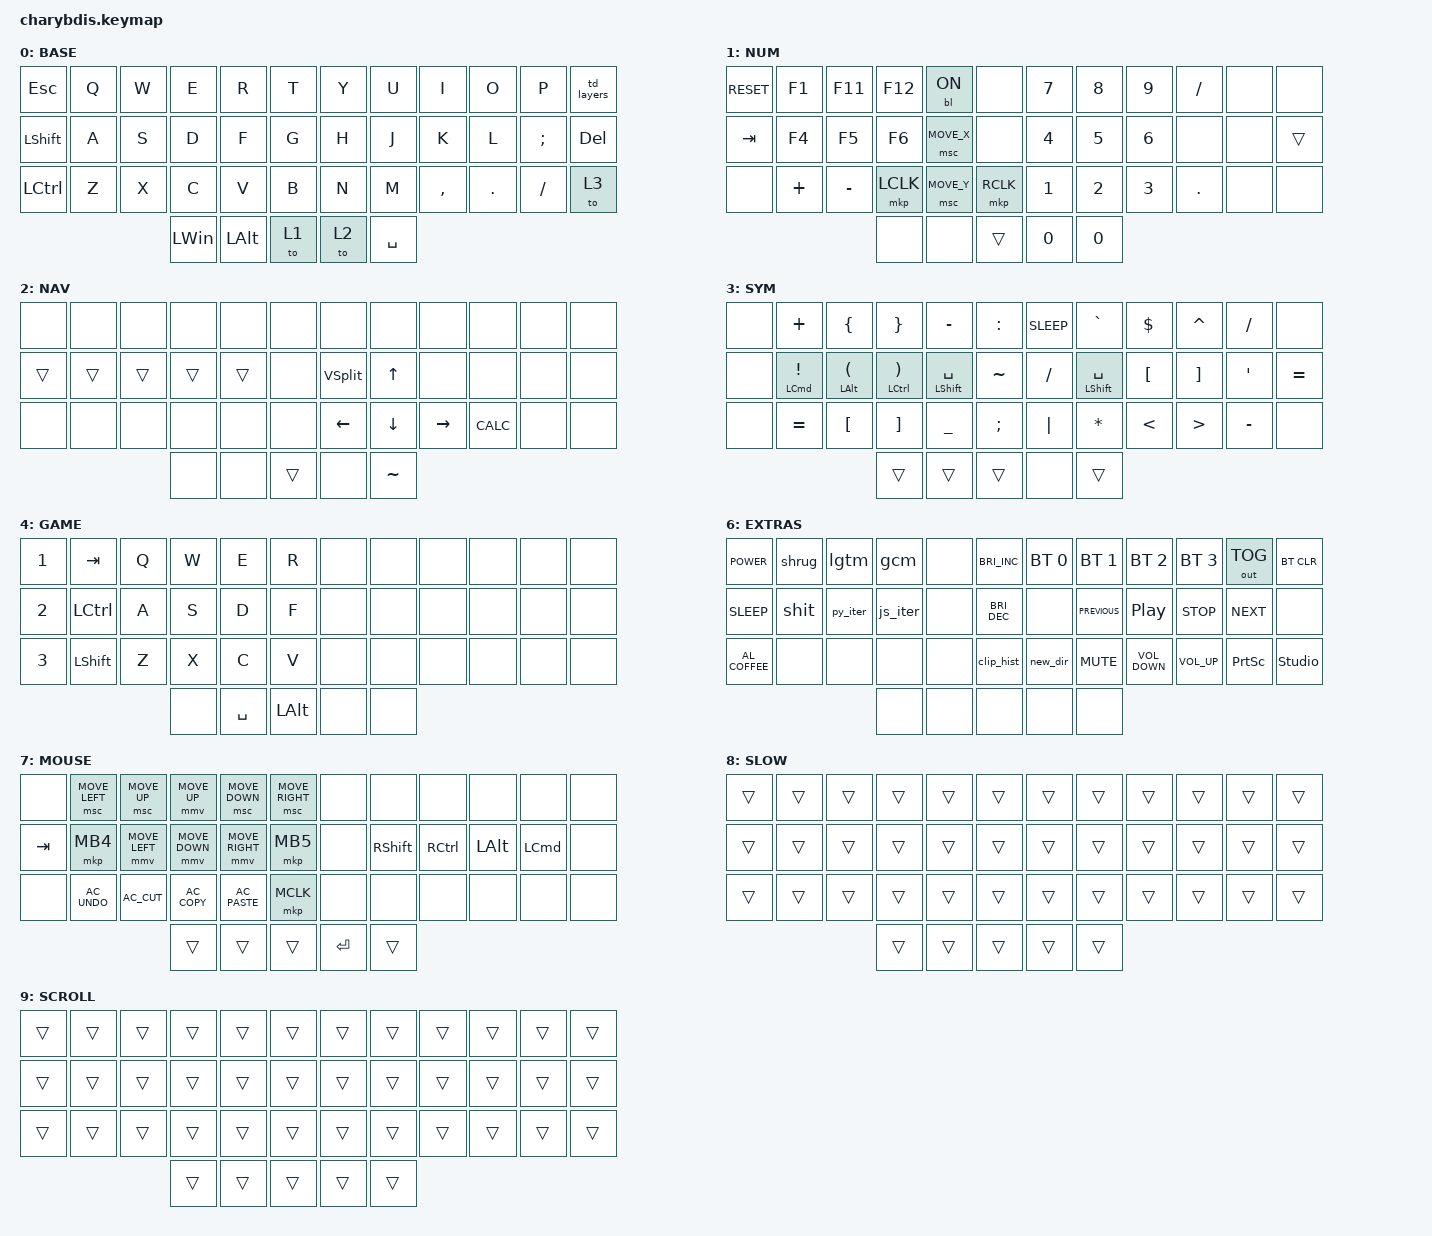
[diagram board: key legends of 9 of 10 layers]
#include <dt-bindings/zmk/mouse.h>
#include <behaviors/mouse_keys.dtsi>
#include "macros.dtsi"
#include <behaviors.dtsi>
#include <dt-bindings/zmk/backlight.h>
#include <dt-bindings/zmk/bt.h>
#include <dt-bindings/zmk/keys.h>
#include <dt-bindings/zmk/outputs.h>
#include <dt-bindings/zmk/pointing.h>
#include <dt-bindings/zmk/pointing.h>
#include <dt-bindings/zmk/pointing.h>

// / {
//     chosen { zmk,matrix_transform = &default_transform; };
// };

/ {
    /* input config for mouse move mode */

    trackball_listener {
        compatible = "zmk,input-behavior-listener";
        device = <&vtrackball>;
        layers = <0 2 7>;
        evt-type = <INPUT_EV_REL>;
        x-input-code = <INPUT_REL_X>;
        y-input-code = <INPUT_REL_Y>;
        scale-multiplier = <1>;
        scale-divisor = <2>;

        // bindings = <&ib_toggle_layer 7>;
    };

    /* input config for snipe mode */

    trackball_snipe_listener {
        compatible = "zmk,input-behavior-listener";
        device = <&vtrackball>;
        layers = <8>;
        evt-type = <INPUT_EV_REL>;
        x-input-code = <INPUT_REL_X>;
        y-input-code = <INPUT_REL_Y>;
        scale-multiplier = <1>;
        scale-divisor = <4>;
    };

    /* input config for mouse scroll mode */

    trackball_scroll_listener {
        compatible = "zmk,input-behavior-listener";
        device = <&vtrackball>;
        layers = <9>;
        evt-type = <INPUT_EV_REL>;
        x-input-code = <INPUT_REL_MISC>;
        y-input-code = <INPUT_REL_WHEEL>;
        y-invert;
        bindings = <&ib_wheel_scaler 1 14>;
    };

    /* define a resolution down scaler only for INPUT_REL_WHEEL */

    ib_wheel_scaler: ib_wheel_scaler {
        compatible = "zmk,input-behavior-scaler";
        #binding-cells = <2>;
        evt-type = <INPUT_EV_REL>;
        input-code = <INPUT_REL_WHEEL>;
    };

    /* adjust cooldown waiting period for mouse key layer after activated */

    ib_toggle_layer: ib_toggle_layer {
        compatible = "zmk,input-behavior-tog-layer";
        #binding-cells = <1>;
        time-to-live-ms = <750>;
    };

    behaviors {
        hm: homerow_mod {
            compatible = "zmk,behavior-hold-tap";
            #binding-cells = <2>;
            flavor = "tap-preferred";
            tapping-term-ms = <175>; // triggers the hold behavior when the tapping-term-ms has expired
            quick-tap-ms = <150>; // If you press a tapped hold-tap again within quick-tap-ms milliseconds of the first press, it will always trigger the tap behavior.
            require-prior-idle-ms = <185>; // like quick-tap-ms however it will apply for any non-modifier key pressed before it
            bindings = <&kp>, <&kp>;

            // hold, tap
        };

        td_cursor: td_scroll_or_cursor {
            compatible = "zmk,behavior-tap-dance";
            #binding-cells = <0>;
            bindings = <&lt 9 ESC>, <&to 8>;

            // hold, tap, double_tap
        };

        httl: ht_two_layers {
            compatible = "zmk,behavior-hold-tap";
            bindings = <&mo>, <&to>;

            #binding-cells = <2>;
            flavor = "balanced";
            tapping-term-ms = <125>;
        };

        td_layers: td_layer_swap {
            compatible = "zmk,behavior-tap-dance";
            #binding-cells = <0>;
            bindings = <&to 0>, <&to 5>, <&to 4>;

            // tap, double_tap, tripple_tap
        };

        td_clk_scrl: td_click_or_scroll {
            compatible = "zmk,behavior-tap-dance";
            #binding-cells = <0>;
            tapping-term-ms = <250>;
            bindings = <&mkp RCLK>, <&mo 9>;

            // tap/hold, double_tap
        };

        td_bore: BASE_or_EXTRA {
            compatible = "zmk,behavior-tap-dance";
            #binding-cells = <0>;
            bindings = <&mo 6>, <&to 0>;
        };
    };

    combos {
        compatible = "zmk,combos";

        CapsWord {
            bindings = <&caps_word>;
            key-positions = <17 18>;
            layers = <0>;
        };

        MiddleClick {
            bindings = <&mkp MCLK>;
            key-positions = <28 37>;
        };

        RightClick {
            bindings = <&mkp RCLK>;
            key-positions = <16 37>;
        };

        BASE_or_EXTRAS {
            bindings = <&td_bore>;
            key-positions = <38 39>;
        };

        // GameLayer {
        //     bindings = <&tog 4>;
        //     key-positions = <8 9>;
        // };
        // PhotoLayer {
        //     bindings = <&tog 5>;
        //     key-positions = <2 3>;
        // };
    };

    // ╭──────┬──────┬──────┬──────┬──────┬──────╮  ╭──────┬──────┬──────┬──────┬──────┬──────╮
    //    00     01     02     03    04      05        06     07     08     09     10     11
    // ├──────┼──────┼──────┼──────┼──────┼──────┤  ├──────┼──────┼──────┼──────┼──────┼──────┤
    //    12     13     14     15    16      17        18     19     20     21     22     23
    // ├──────┼──────┼──────┼──────┼──────┼──────┤  ├──────┼──────┼──────┼──────┼──────┼──────┤
    //    24     25     26     27    28      29        30     31     32     33     34     35
    // ╰──────┴──────┴──────┼──────┼──────┼──────┤  ├──────┼──────┼──────┴──────┴──────┴──────╯
    //                         36     37     38        39     40
    //                      ╰──────┴──────┴──────╯  ╰──────┴──────╯
    // #define BASE    0
    // #define NUM     1
    // #define NAV     2
    // #define SYM     3
    // #define GAME    4
    // #define PHOTOS  5
    // #define EXTRAS  6
    // #define MOUSE   7
    // #define SLOW    8
    // #define SCROLL  9

    keymap {
        compatible = "zmk,keymap";

        BASE {
            bindings = <
&kp ESC         &kp Q  &kp W  &kp E         &kp R         &kp T    &kp Y  &kp U      &kp I      &kp O       &kp P          &td_layers
&kp LEFT_SHIFT  &kp A  &kp S  &kp D         &kp F         &kp G    &kp H  &kp J      &kp K      &kp L       &kp SEMICOLON  &kp DEL
&kp LCTRL       &kp Z  &kp X  &kp C         &kp V         &kp B    &kp N  &kp M      &kp COMMA  &kp PERIOD  &kp FSLH       &to 3
                              &kp LEFT_WIN  &kp LEFT_ALT  &to 1    &to 2  &kp SPACE
            >;
        };

        NUM {
            bindings = <
&kp C_RESET  &kp F1    &kp F11    &kp F12    &bl BL_ON      &none        &kp N7        &kp N8        &kp N9        &kp SLASH   &none  &none
&kp TAB      &kp F4    &kp F5     &kp F6     &msc MOVE_X 0  &none        &kp NUMBER_4  &kp N5        &kp NUMBER_6  &none       &none  &trans
&none        &kp PLUS  &kp MINUS  &mkp LCLK  &msc MOVE_Y 0  &mkp RCLK    &kp NUMBER_1  &kp NUMBER_2  &kp NUMBER_3  &kp PERIOD  &none  &none
                                  &none      &none          &trans       &kp N0        &kp N0
            >;
        };

        NAV {
            bindings = <
&none   &none   &none   &none   &none   &none     &none           &none           &none            &none       &none  &none
&trans  &trans  &trans  &trans  &trans  &none     &VSplit         &kp UP_ARROW    &none            &none       &none  &none
&none   &none   &none   &none   &none   &none     &kp LEFT_ARROW  &kp DOWN_ARROW  &kp RIGHT_ARROW  &kp K_CALC  &none  &none
                        &none   &none   &trans    &none           &kp TILDE
            >;
        };

        SYM {
            bindings = <
&none  &kp PLUS       &kp LEFT_BRACE     &kp RIGHT_BRACE  &kp MINUS             &kp COLON        &kp K_SLEEP  &kp GRAVE             &kp DLLR          &kp CARET          &kp SLASH  &none
&none  &hm LCMD EXCL  &hm LEFT_ALT LPAR  &hm LCTRL RPAR   &hm LEFT_SHIFT SPACE  &kp TILDE        &kp SLASH    &hm LEFT_SHIFT SPACE  &kp LEFT_BRACKET  &kp RIGHT_BRACKET  &kp SQT    &kp EQUAL
&none  &kp EQUAL      &kp LBKT           &kp RBKT         &kp UNDERSCORE        &kp SEMICOLON    &kp PIPE     &kp ASTRK             &kp LESS_THAN     &kp GREATER_THAN   &kp MINUS  &none
                                         &trans           &trans                &trans           &none        &trans
            >;
        };

        GAME {
            bindings = <
&kp N1  &kp TAB    &kp Q  &kp W  &kp E      &kp R           &none  &none  &none  &none  &none  &none
&kp N2  &kp LCTRL  &kp A  &kp S  &kp D      &kp F           &none  &none  &none  &none  &none  &none
&kp N3  &kp LSHFT  &kp Z  &kp X  &kp C      &kp V           &none  &none  &none  &none  &none  &none
                          &none  &kp SPACE  &kp LEFT_ALT    &none  &none
            >;
        };

        PHOTOS {
            bindings = <
&trans          &kp LA(LC(LS(Z)))  &kp LA(LC(LS(E)))  &kp LA(LC(LS(A)))  &kp LA(LC(LS(S)))  &kp LA(LC(LS(B)))    &none   &none   &none  &none  &none  &none
&kp LC(LA(E))   &kp LEFT           &kp DOWN           &kp UP             &kp RIGHT          &kp LCTRL            &none   &none   &none  &none  &none  &trans
&kp LS(DELETE)  &kp LA(LS(A))      &kp LA(KP_N1)      &kp LA(KP_N2)      &kp LA(KP_N3)      &none                &none   &none   &none  &none  &none  &none
                                                      &trans             &trans             &trans               &trans  &trans
            >;
        };

        EXTRAS {
            bindings = <
&kp C_POWER      &shrug  &lgtm     &gcm      &none  &kp C_BRIGHTNESS_INC    &bt BT_SEL 0  &bt BT_SEL 1    &bt BT_SEL 2       &bt BT_SEL 3     &out OUT_TOG     &bt BT_CLR
&kp C_SLEEP      &shit   &py_iter  &js_iter  &none  &kp C_BRIGHTNESS_DEC    &none         &kp C_PREVIOUS  &kp C_PLAY_PAUSE   &kp C_STOP       &kp C_NEXT       &none
&kp C_AL_COFFEE  &none   &none     &none     &none  &clip_hist              &new_dir      &kp K_MUTE      &kp C_VOLUME_DOWN  &kp C_VOLUME_UP  &kp PRINTSCREEN  &studio_unlock
                                   &none     &none  &none                   &none         &none
            >;
        };

        MOUSE {
            bindings = <
&none    &msc MOVE_LEFT  &msc MOVE_UP    &mmv MOVE_UP    &msc MOVE_DOWN   &msc MOVE_RIGHT    &none       &none            &none      &none         &none     &none
&kp TAB  &mkp MB4        &mmv MOVE_LEFT  &mmv MOVE_DOWN  &mmv MOVE_RIGHT  &mkp MB5           &none       &kp RIGHT_SHIFT  &kp RCTRL  &kp LEFT_ALT  &kp LCMD  &none
&none    &kp C_AC_UNDO   &kp C_AC_CUT    &kp C_AC_COPY   &kp C_AC_PASTE   &mkp MCLK          &none       &none            &none      &none         &none     &none
                                         &trans          &trans           &trans             &kp RETURN  &trans
            >;
        };

        SLOW {
            bindings = <
&trans  &trans  &trans  &trans  &trans  &trans    &trans  &trans  &trans  &trans  &trans  &trans
&trans  &trans  &trans  &trans  &trans  &trans    &trans  &trans  &trans  &trans  &trans  &trans
&trans  &trans  &trans  &trans  &trans  &trans    &trans  &trans  &trans  &trans  &trans  &trans
                        &trans  &trans  &trans    &trans  &trans
            >;
        };

        SCROLL {
            bindings = <
&trans  &trans  &trans  &trans  &trans  &trans    &trans  &trans  &trans  &trans  &trans  &trans
&trans  &trans  &trans  &trans  &trans  &trans    &trans  &trans  &trans  &trans  &trans  &trans
&trans  &trans  &trans  &trans  &trans  &trans    &trans  &trans  &trans  &trans  &trans  &trans
                        &trans  &trans  &trans    &trans  &trans
            >;
        };
    };
};
